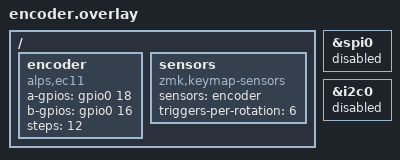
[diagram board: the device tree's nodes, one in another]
// Disable SPI0/I2C0 on left peripheral to free GPIO0.18/16 for encoder
&spi0 {
    status = "disabled";
};

&i2c0 {
    status = "disabled";
};

/ {
    encoder: encoder {
        compatible = "alps,ec11";
        a-gpios = <&gpio0 18 (GPIO_ACTIVE_HIGH | GPIO_PULL_UP)>;
        b-gpios = <&gpio0 16 (GPIO_ACTIVE_HIGH | GPIO_PULL_UP)>;
        steps = <12>;
        status = "okay";
    };

    sensors: sensors {
        compatible = "zmk,keymap-sensors";
        sensors = <&encoder>;
        triggers-per-rotation = <6>;
    };
};
